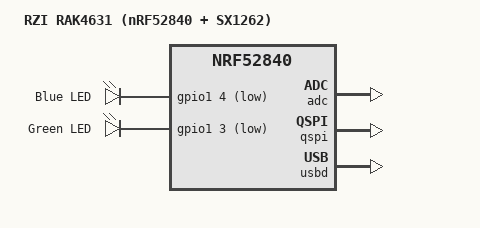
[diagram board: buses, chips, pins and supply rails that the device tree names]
/* SPDX-License-Identifier: Apache-2.0 */

/dts-v1/;
#include <rakwireless/rzi_rak4630.dtsi>
#include "rzi_rak4631-partitions.dtsi"
#include <zephyr/dt-bindings/gpio/gpio.h>
#include "rzi_rak4631-pinctrl.dtsi"

/ {
	model = "RZI RAK4631 (nRF52840 + SX1262)";
	compatible = "rakwireless,rzi-rak4631-nrf52840";

	chosen {
		zephyr,console = &uart1;
		zephyr,shell-uart = &uart1;
		zephyr,uart-mcumgr = &uart1;
		zephyr,lorawan-transceiver = &lora;
	};

	leds {
		compatible = "gpio-leds";

		blue_led: led_2 {
			gpios = <&gpio1 4 GPIO_ACTIVE_LOW>;
			label = "Blue LED";
		};

		green_led: led_1 {
			gpios = <&gpio1 3 GPIO_ACTIVE_LOW>;
			label = "Green LED";
		};
	};

	aliases {
		led0 = &blue_led;
		led1 = &green_led;
		lora0 = &lora;
		watchdog0 = &wdt0;
		rzi-at-uart = &cdc_acm_uart0;
	};

	/*
	 * Placeholder OTAA values. Applications override zephyr,user in an
	 * overlay; samples that omit an overlay use these zeros.
	 */
	zephyr,user {
		user-lorawan-device-eui = <0x00 0x00 0x00 0x00 0x00 0x00 0x00 0x00>;
		user-lorawan-join-eui = <0x00 0x00 0x00 0x00 0x00 0x00 0x00 0x00>;
		user-lorawan-gen_app-key = <0x00 0x00 0x00 0x00 0x00 0x00 0x00 0x00
					    0x00 0x00 0x00 0x00 0x00 0x00 0x00 0x00>;
		user-lorawan-app-key = <0x00 0x00 0x00 0x00 0x00 0x00 0x00 0x00
					0x00 0x00 0x00 0x00 0x00 0x00 0x00 0x00>;
		user-lorawan-region = "EU_868";
	};
};

&adc {
	status = "okay";
};

&qspi {
	status = "okay";
	pinctrl-0 = <&qspi_default>;
	pinctrl-1 = <&qspi_sleep>;
	pinctrl-names = "default", "sleep";
};

zephyr_udc0: &usbd {
	compatible = "nordic,nrf-usbd";
	status = "okay";

	cdc_acm_uart0: cdc_acm_uart0 {
		compatible = "zephyr,cdc-acm-uart";
	};
};
